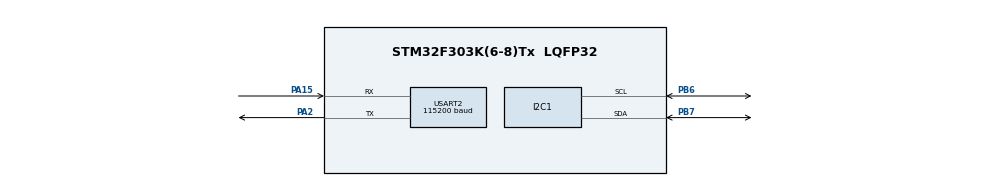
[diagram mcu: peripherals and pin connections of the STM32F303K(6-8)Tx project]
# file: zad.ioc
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Dma.Request0=USART2_RX
Dma.Request1=USART2_TX
Dma.USART2_RX.0.Direction=DMA_PERIPH_TO_MEMORY
Dma.USART2_RX.0.Instance=DMA1_Channel6
Dma.USART2_RX.0.MemDataAlignment=DMA_MDATAALIGN_BYTE
Dma.USART2_RX.0.MemInc=DMA_MINC_ENABLE
Dma.USART2_RX.0.Mode=DMA_CIRCULAR
Dma.USART2_RX.0.PeriphDataAlignment=DMA_PDATAALIGN_BYTE
Dma.USART2_RX.0.PeriphInc=DMA_PINC_DISABLE
Dma.USART2_RX.0.Priority=DMA_PRIORITY_MEDIUM
Dma.USART2_TX.1.Direction=DMA_MEMORY_TO_PERIPH
Dma.USART2_TX.1.Instance=DMA1_Channel7
Dma.USART2_TX.1.MemDataAlignment=DMA_MDATAALIGN_BYTE
Dma.USART2_TX.1.MemInc=DMA_MINC_ENABLE
Dma.USART2_TX.1.Mode=DMA_NORMAL
Dma.USART2_TX.1.PeriphDataAlignment=DMA_PDATAALIGN_BYTE
Dma.USART2_TX.1.PeriphInc=DMA_PINC_DISABLE
Dma.USART2_TX.1.Priority=DMA_PRIORITY_MEDIUM
I2C1.I2C_Rise_Time=0
I2C1.OwnAddress=1
I2C1.Timing=0x00101D2B
Mcu.Family=STM32F3
Mcu.Name=STM32F303K(6-8)Tx
Mcu.Package=LQFP32
NVIC.DMA1_Channel6_IRQn=true\:0\:0\:false\:false\:true\:false\:true\:true
NVIC.DMA1_Channel7_IRQn=true\:0\:0\:false\:false\:true\:false\:true\:true
NVIC.I2C1_EV_IRQn=true\:0\:0\:false\:false\:true\:true\:true\:true
NVIC.PriorityGroup=NVIC_PRIORITYGROUP_4
NVIC.USART2_IRQn=true\:0\:0\:false\:false\:true\:true\:true\:true
PA15.Mode=Asynchronous
PA15.Signal=USART2_RX
PA2.Mode=Asynchronous
PA2.Signal=USART2_TX
PB6.Mode=I2C
PB6.Signal=I2C1_SCL
PB7.Mode=I2C
PB7.Signal=I2C1_SDA
ProjectManager.HeapSize=0x200
ProjectManager.StackSize=0x400
ProjectManager.TargetToolchain=STM32CubeIDE
RCC.AHBFreq_Value=8000000
RCC.APB1Freq_Value=8000000
RCC.APB2Freq_Value=8000000
RCC.CortexFreq_Value=8000000
RCC.HSE_VALUE=8000000
RCC.HSI_VALUE=8000000
RCC.SYSCLKFreq_VALUE=8000000
USART2.BaudRate=115200
USART2.VirtualMode-Asynchronous=VM_ASYNC
board=custom

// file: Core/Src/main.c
/* USER CODE BEGIN Header */
/**
  ******************************************************************************
  * @file           : main.c
  * @brief          : Main program body
  ******************************************************************************
  * @attention
  *
  * Copyright (c) 2024 STMicroelectronics.
  * All rights reserved.
  *
  * This software is licensed under terms that can be found in the LICENSE file
  * in the root directory of this software component.
  * If no LICENSE file comes with this software, it is provided AS-IS.
  *
  ******************************************************************************
  */
/* USER CODE END Header */
#include "main.h"
#include "dma.h"
#include "i2c.h"
#include "usart.h"
#include "gpio.h"
#include "HTS221.h"
#include "LPS25HB.h"
#include "stdio.h"
#include "string.h"
#include <math.h>

/* USER CODE BEGIN Includes */
uint8_t humidity = 0;
float temperature = 0;
float mag[3], acc[3];
float pressure = 0;
float refference = 0;
float constant = 0.0342;
float height = 0;
float pressureatsealevel = 101325;
float T = 0;
char formated_text[30], value_x[10], value_y[10], value_z[10];

/* USER CODE END Includes */

void SystemClock_Config(void);

int main(void)
{

  /* MCU Configuration--------------------------------------------------------*/

  /* Reset of all peripherals, Initializes the Flash interface and the Systick. */
  LL_APB2_GRP1_EnableClock(LL_APB2_GRP1_PERIPH_SYSCFG);
  LL_APB1_GRP1_EnableClock(LL_APB1_GRP1_PERIPH_PWR);

  /* System interrupt init*/
  NVIC_SetPriorityGrouping(NVIC_PRIORITYGROUP_4);

  /* SysTick_IRQn interrupt configuration */
  NVIC_SetPriority(SysTick_IRQn, NVIC_EncodePriority(NVIC_GetPriorityGrouping(),15, 0));

  /* Configure the system clock */
  SystemClock_Config();

  /* Initialize all configured peripherals */
  MX_GPIO_Init();
  MX_DMA_Init();
  MX_USART2_UART_Init();
  MX_I2C1_Init();
  hts221_init();
  lps25hb_init();

  /* Infinite loop */
  /* USER CODE BEGIN WHILE */
  refference = lps25hb_get_pressure();

  while (1)
  {
	  pressure = lps25hb_get_pressure();
	  height = (float)44330.00 * (1-pow(pressure/refference,1/5.255));
	  temperature=lps25hb_get_temperature();
	  humidity=hts221_get_humidity();
	  memset(formated_text, '\0', sizeof(formated_text));
	  sprintf(formated_text, "%.1f,%d%,%.2f,%.2f\n\r", temperature,humidity,pressure, height);
	  USART2_PutBuffer((uint8_t*)formated_text, strlen(formated_text));
	  LL_mDelay(2000);

  }
  /* USER CODE END 3 */
}

void SystemClock_Config(void)
{
  LL_FLASH_SetLatency(LL_FLASH_LATENCY_0);
  while(LL_FLASH_GetLatency()!= LL_FLASH_LATENCY_0)
  {
  }
  LL_RCC_HSI_Enable();

   /* Wait till HSI is ready */
  while(LL_RCC_HSI_IsReady() != 1)
  {

  }
  LL_RCC_HSI_SetCalibTrimming(16);
  LL_RCC_SetAHBPrescaler(LL_RCC_SYSCLK_DIV_1);
  LL_RCC_SetAPB1Prescaler(LL_RCC_APB1_DIV_1);
  LL_RCC_SetAPB2Prescaler(LL_RCC_APB2_DIV_1);
  LL_RCC_SetSysClkSource(LL_RCC_SYS_CLKSOURCE_HSI);

   /* Wait till System clock is ready */
  while(LL_RCC_GetSysClkSource() != LL_RCC_SYS_CLKSOURCE_STATUS_HSI)
  {

  }
  LL_Init1msTick(8000000);
  LL_SetSystemCoreClock(8000000);
  LL_RCC_SetI2CClockSource(LL_RCC_I2C1_CLKSOURCE_HSI);
}

void Error_Handler(void)
{
  __disable_irq();
  while (1)
  {
  }
}
